# R7FA6M1AD register map
Vendor: Renesas; Series: RA6; File version: 1.2
CPU: CM4 r0p1, little endian, MPU, FPU, VTOR, 4 interrupt priority bits
Registers are 8-bit, read-write, reset 0x0 unless marked. A register's access mark holds for its fields unless they carry their own. Offsets are from the block's base; [hi:lo] are bit positions; {n}, {i} and the like mark numbered series; 'fields as' and 'values as' point back to an identical list.

## USBFS — USB 2.0 FS Module
Base 0x40090000
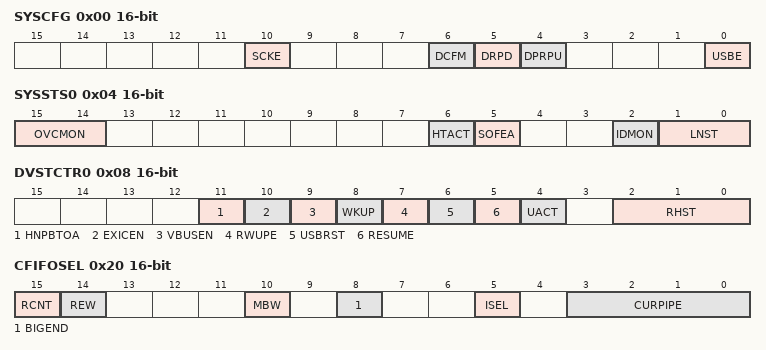
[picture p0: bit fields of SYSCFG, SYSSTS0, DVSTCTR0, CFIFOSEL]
0x00 SYSCFG 16-bit — System Configuration Control Register
  [10] SCKE — USB Clock Enable
  [6] DCFM — Controller Function Select
  [5] DRPD — D+/D- Line Resistor Control
  [4] DPRPU — D+ Line Resistor Control
  [0] USBE — USB Operation Enable
0x04 SYSSTS0 16-bit ro reset not defined — System Configuration Status Register 0
  [15:14] OVCMON — External USB0_OVRCURA/ USB0_OVRCURB Input Pin MonitorThe OCVMON[1] bit indicates the status of the USBHS_OVRCURA pin. The OCVMON[0] bit indicates the status of the USBHS_OVRCURB pin.
  [6] HTACT — USB Host Sequencer Status Monitor
  [5] SOFEA — Active Monitor When the Host Controller is Selected.
  [2] IDMON — External ID0 Input Pin Monitor
  [1:0] LNST — USB Data Line Status Monitor
0x08 DVSTCTR0 16-bit — Device State Control Register 0
  [11] HNPBTOA — Host Negotiation Protocol (HNP) Control This bit is used when switching from device B to device A while in OTG mode. If the HNPBTOA bit is 1, the internal function control keeps the suspended state until the HNP processing ends even though SYSCFG.DPRPU = 0 or SYSCFG.DCFM = 1 is set.
  [10] EXICEN — USB0_EXICEN Output Pin Control
  [9] VBUSEN — USB0_VBUSEN Output Pin Control
  [8] WKUP — Wakeup Output
  [7] RWUPE — Wakeup Detection Enable
  [6] USBRST — USB Bus Reset Output
  [5] RESUME — Resume Output
  [4] UACT — USB Bus Enable
  [2:0] RHST ro — USB Bus Reset Status
0x14 CFIFO 16-bit — CFIFO Port Register
  [15:0] FIFOPORT — FIFO PortRead receive data from the FIFO buffer or write transmit data to the FIFO buffer by accessing these bits.
0x14 CFIFOL (alternate view of CFIFO) — CFIFO Port Register L
0x18 D0FIFO 16-bit — D0FIFO Port Register
  fields as CFIFO
0x18 D0FIFOL (alternate view of D0FIFO) — D0FIFO Port Register L
0x1C D1FIFO 16-bit — D1FIFO Port Register
  fields as CFIFO
0x1C D1FIFOL (alternate view of D1FIFO) — D1FIFO Port Register L
0x20 CFIFOSEL 16-bit — CFIFO Port Select Register
  [15] RCNT — Read Count Mode
  [14] REW ro — Buffer Pointer Rewind
  [10] MBW — CFIFO Port Access Bit Width
  [8] BIGEND — CFIFO Port Endian Control
  [5] ISEL — CFIFO Port Access Direction When DCP is Selected
  [3:0] CURPIPE — CFIFO Port Access Pipe Specification
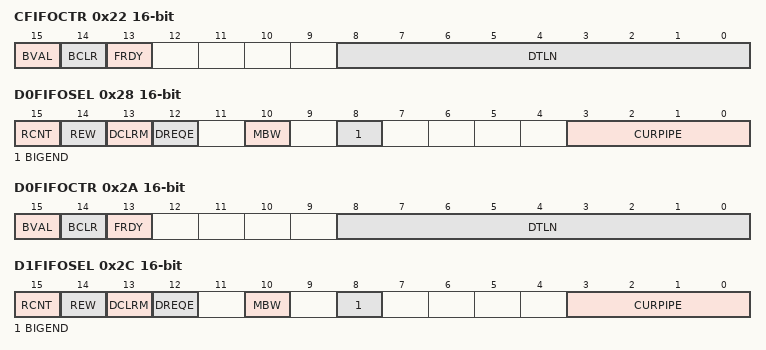
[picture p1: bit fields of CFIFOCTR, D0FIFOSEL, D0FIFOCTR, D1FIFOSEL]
0x22 CFIFOCTR 16-bit — CFIFO Port Control Register
  [15] BVAL — Buffer Memory Valid Flag
  [14] BCLR ro — CPU Buffer Clear
  [13] FRDY ro — FIFO Port Ready
  [8:0] DTLN ro — Receive Data LengthIndicates the length of the receive data.
0x28 D0FIFOSEL 16-bit — D0FIFO Port Select Register
  [15] RCNT — Read Count Mode
  [14] REW ro — Buffer Pointer Rewind
  [13] DCLRM — Auto Buffer Memory Clear Mode Accessed after Specified Pipe Data is Read
  [12] DREQE — DMA/DTC Transfer Request Enable
  [10] MBW — FIFO Port Access Bit Width
  [8] BIGEND — FIFO Port Endian Control
  [3:0] CURPIPE — FIFO Port Access Pipe Specification
0x2A D0FIFOCTR 16-bit — D0FIFO Port Control Register
  fields as CFIFOCTR
0x2C D1FIFOSEL 16-bit — D1FIFO Port Select Register
  fields as D0FIFOSEL
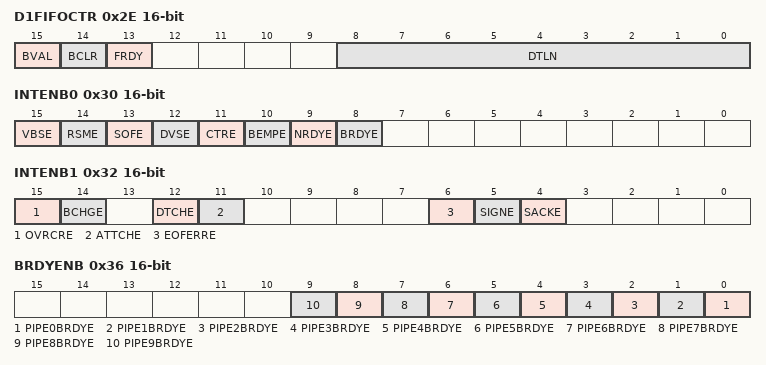
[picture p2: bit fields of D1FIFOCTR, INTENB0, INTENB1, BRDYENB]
0x2E D1FIFOCTR 16-bit — D1FIFO Port Control Register
  fields as CFIFOCTR
0x30 INTENB0 16-bit — Interrupt Enable Register 0
  [15] VBSE — VBUS Interrupt Enable
  [14] RSME — Resume Interrupt Enable
  [13] SOFE — Frame Number Update Interrupt Enable
  [12] DVSE — Device State Transition Interrupt Enable
  [11] CTRE — Control Transfer Stage Transition Interrupt Enable
  [10] BEMPE — Buffer Empty Interrupt Enable
  [9] NRDYE — Buffer Not Ready Response Interrupt Enable
  [8] BRDYE — Buffer Ready Interrupt Enable
0x32 INTENB1 16-bit — Interrupt Enable Register 1
  [15] OVRCRE — Overcurrent Input Change Interrupt Enable
  [14] BCHGE — USB Bus Change Interrupt Enable
  [12] DTCHE — Disconnection Detection Interrupt Enable
  [11] ATTCHE — Connection Detection Interrupt Enable
  [6] EOFERRE — EOF Error Detection Interrupt Enable
  [5] SIGNE — Setup Transaction Error Interrupt Enable
  [4] SACKE — Setup Transaction Normal Response Interrupt Enable
0x36 BRDYENB 16-bit — BRDY Interrupt Enable Register
  [n] PIPE{n}BRDYE (n=0..9) — BRDY Interrupt Enable for PIPE{n}
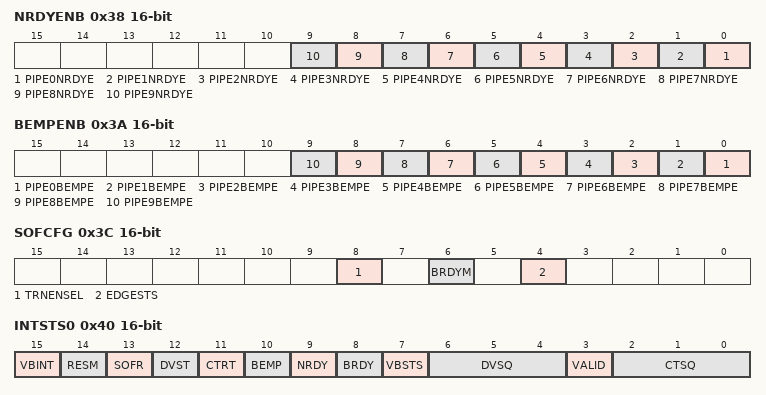
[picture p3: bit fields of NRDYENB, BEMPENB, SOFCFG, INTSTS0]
0x38 NRDYENB 16-bit — NRDY Interrupt Enable Register
  [n] PIPE{n}NRDYE (n=0..9) — NRDY Interrupt Enable for PIPE{n}
0x3A BEMPENB 16-bit — BEMP Interrupt Enable Register
  [n] PIPE{n}BEMPE (n=0..9) — BEMP Interrupt Enable for PIPE{n}
0x3C SOFCFG 16-bit — SOF Output Configuration Register
  [8] TRNENSEL — Transaction,Enabled Time Select
  [6] BRDYM — BRDY Interrupt Status Clear Timing
  [4] EDGESTS ro — Edge Interrupt Output Status Monitor
0x40 INTSTS0 16-bit (reset mask 0xFF7F) — Interrupt Status Register 0
  [15] VBINT write-0-clears read-modifies — VBUS Interrupt Status
  [14] RESM write-0-clears read-modifies — Resume Interrupt Status
  [13] SOFR write-0-clears read-modifies — Frame Number Refresh Interrupt Status
  [12] DVST write-0-clears read-modifies — Device State Transition Interrupt Status
  [11] CTRT write-0-clears read-modifies — Control Transfer Stage Transition Interrupt Status
  [10] BEMP ro — Buffer Empty Interrupt Status
  [9] NRDY ro — Buffer Not Ready Interrupt Status
  [8] BRDY ro — Buffer Ready Interrupt Status
  [7] VBSTS ro — VBUS Input Status
  [6:4] DVSQ ro — Device State
  [3] VALID — USB Request Reception
  [2:0] CTSQ ro — Control Transfer Stage
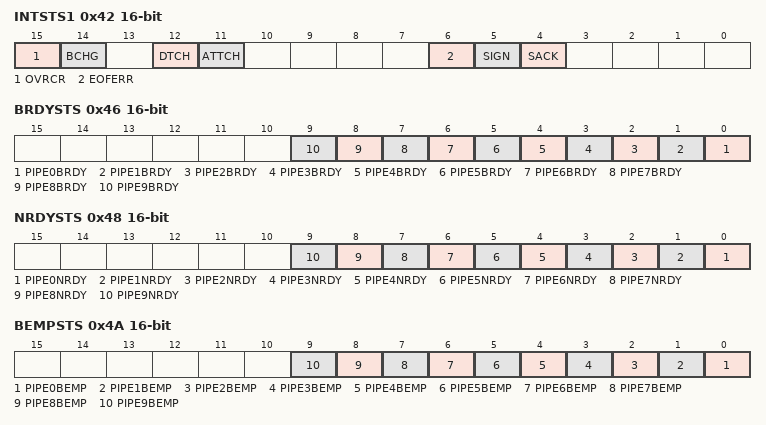
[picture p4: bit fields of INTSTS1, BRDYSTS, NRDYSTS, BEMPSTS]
0x42 INTSTS1 16-bit — Interrupt Status Register 1
  [15] OVRCR write-0-clears read-modifies — Overcurrent Input Change Interrupt Status
  [14] BCHG write-0-clears read-modifies — USB Bus Change Interrupt Status
  [12] DTCH write-0-clears read-modifies — USB Disconnection Detection Interrupt Status
  [11] ATTCH write-0-clears read-modifies — ATTCH Interrupt Status
  [6] EOFERR write-0-clears read-modifies — EOF Error Detection Interrupt Status
  [5] SIGN write-0-clears read-modifies — Setup Transaction Error Interrupt Status
  [4] SACK write-0-clears read-modifies — Setup Transaction Normal Response Interrupt Status
0x46 BRDYSTS 16-bit — BRDY Interrupt Status Register
  [n] PIPE{n}BRDY write-0-clears read-modifies (n=0..9) — BRDY Interrupt Status for PIPE{n}
0x48 NRDYSTS 16-bit — NRDY Interrupt Status Register
  [n] PIPE{n}NRDY write-0-clears read-modifies (n=0..9) — NRDY Interrupt Status for PIPE{n}
0x4A BEMPSTS 16-bit — BEMP Interrupt Status Register
  [n] PIPE{n}BEMP write-0-clears read-modifies (n=0..9) — BEMP Interrupt Status for PIPE{n}
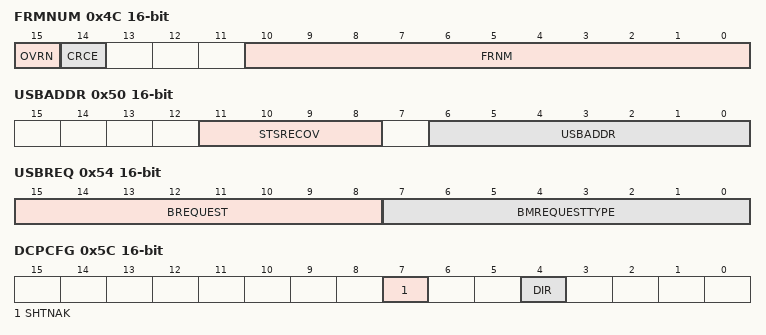
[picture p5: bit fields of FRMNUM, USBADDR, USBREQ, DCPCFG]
0x4C FRMNUM 16-bit — Frame Number Register
  [15] OVRN — Overrun/Underrun Detection Status
  [14] CRCE — Receive Data Error
  [10:0] FRNM ro — Frame NumberLatest frame number
0x4E DVCHGR 16-bit — Device State Change Register
  [15] DVCHG — Device State Change
0x50 USBADDR 16-bit — USB Address Register
  [11:8] STSRECOV — Status Recovery
  [6:0] USBADDR — USB AddressWhen the function controller is selected, these bits indicate the USB address assigned by the host when the SET_ADDRESS request is successfully processed.
0x54 USBREQ 16-bit — USB Request Type Register
  [15:8] BREQUEST — RequestThese bits store the USB request bRequest value.
  [7:0] BMREQUESTTYPE — Request TypeThese bits store the USB request bmRequestType value.
0x56 USBVAL 16-bit — USB Request Value Register
  [15:0] WVALUE — ValueThese bits store the USB request wValue value.
0x58 USBINDX 16-bit — USB Request Index Register
  [15:0] WINDEX — IndexThese bits store the USB request wIndex value.
0x5A USBLENG 16-bit — USB Request Length Register
  [15:0] WLENGTUH — LengthThese bits store the USB request wLength value.
0x5C DCPCFG 16-bit — DCP Configuration Register
  [7] SHTNAK — Pipe Disabled at End of Transfer
  [4] DIR — Transfer Direction
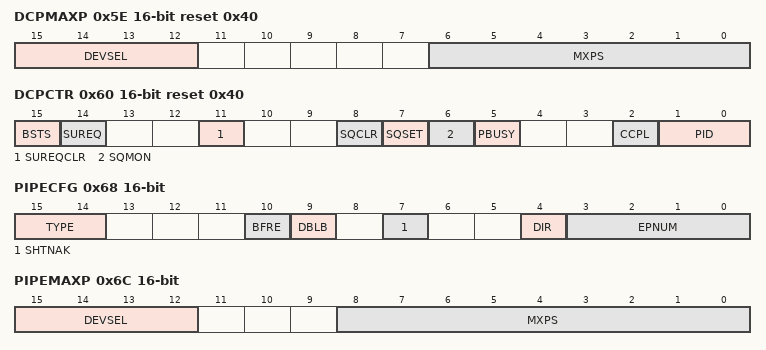
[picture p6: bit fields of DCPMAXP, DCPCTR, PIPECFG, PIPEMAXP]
0x5E DCPMAXP 16-bit reset 0x40 — DCP Maximum Packet Size Register
  [15:12] DEVSEL — Device Select
  [6:0] MXPS — Maximum Packet SizeThese bits set the maximum amount of data (maximum packet size) in payloads for the DCP.
0x60 DCPCTR 16-bit reset 0x40 — DCP Control Register
  [15] BSTS ro — Buffer Status
  [14] SUREQ — Setup Token Transmission
  [11] SUREQCLR — SUREQ Bit Clear
  [8] SQCLR — Sequence Toggle Bit Clear
  [7] SQSET — Sequence Toggle Bit Set
  [6] SQMON ro — Sequence Toggle Bit Monitor
  [5] PBUSY ro — Pipe Busy
  [2] CCPL — Control Transfer End Enable
  [1:0] PID — Response PID
0x64 PIPESEL 16-bit — Pipe Window Select Register
  [3:0] PIPESEL — Pipe Window Select
0x68 PIPECFG 16-bit — Pipe Configuration Register
  [15:14] TYPE — Transfer Type
  [10] BFRE — BRDY Interrupt Operation Specification
  [9] DBLB — Double Buffer Mode
  [7] SHTNAK — Pipe Disabled at End of Transfer
  [4] DIR — Transfer Direction
  [3:0] EPNUM — Endpoint NumberThese bits specify the endpoint number for the selected pipe.Setting 0000b means unused pipe.
0x6C PIPEMAXP 16-bit (reset mask 0xFFBF) — Pipe Maximum Packet Size Register
  [15:12] DEVSEL — Device Select
  [8:0] MXPS — Maximum Packet SizePIPE1 and PIPE2: 1 byte (001h) to 256 bytes (100h)PIPE3 to PIPE5: 8 bytes (008h), 16 bytes (010h), 32 bytes (020h), 64 bytes (040h) (Bits [8:7] and [2:0] are not provided.)PIPE6 to PIPE9: 1 byte (001h) to 64 bytes (040h) (Bits [8:7] are not provided.)
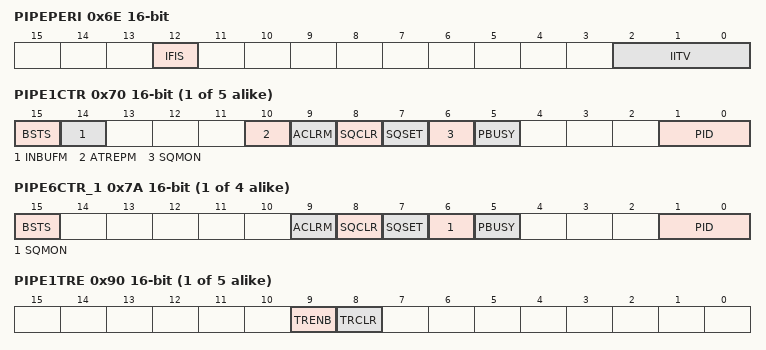
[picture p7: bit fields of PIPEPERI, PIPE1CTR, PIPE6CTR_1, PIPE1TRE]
0x6E PIPEPERI 16-bit — Pipe Cycle Control Register
  [12] IFIS — Isochronous IN Buffer Flush
  [2:0] IITV — Interval Error Detection IntervalSpecifies the interval error detection timing for the selected pipe in terms of frames, which is expressed as nth power of 2.
{0x6E+2i} PIPE{i}CTR (i=1..5) 16-bit — Pipe {i} Control Register
  [15] BSTS ro — Buffer Status
  [14] INBUFM ro — Transmit Buffer Monitor
  [10] ATREPM — Auto Response Mode
  [9] ACLRM — Auto Buffer Clear Mode
  [8] SQCLR wo — Sequence Toggle Bit Clear
  [7] SQSET wo — Sequence Toggle Bit Set
  [6] SQMON ro — Sequence Toggle Bit Confirmation
  [5] PBUSY ro — Pipe Busy
  [1:0] PID — Response PID
{0x6E+2i} PIPE{i}CTR_1 (i=6..9) 16-bit — Pipe {i} Control Register
  [15] BSTS ro — Buffer Status
  [9] ACLRM — Auto Buffer Clear Mode
  [8] SQCLR wo — Sequence Toggle Bit Clear
  [7] SQSET wo — Sequence Toggle Bit Set
  [6] SQMON ro — Sequence Toggle Bit Confirmation
  [5] PBUSY ro — Pipe Busy
  [1:0] PID — Response PID
{0x8C+4i} PIPE{i}TRE (i=1..5) 16-bit — Pipe {i} Transaction Counter Enable Register
  [9] TRENB — Transaction Counter Enable
  [8] TRCLR — Transaction Counter Clear
{0x8E+4i} PIPE{i}TRN (i=1..5) 16-bit — Pipe {i} Transaction Counter Register
  [15:0] TRNCNT — Transaction Counter
{0xD0+2i} DEVADD{i} (i=0..5) 16-bit — Device Address {i} Configuration Register
  [7:6] USBSPD — Transfer Speed of Communication Target Device
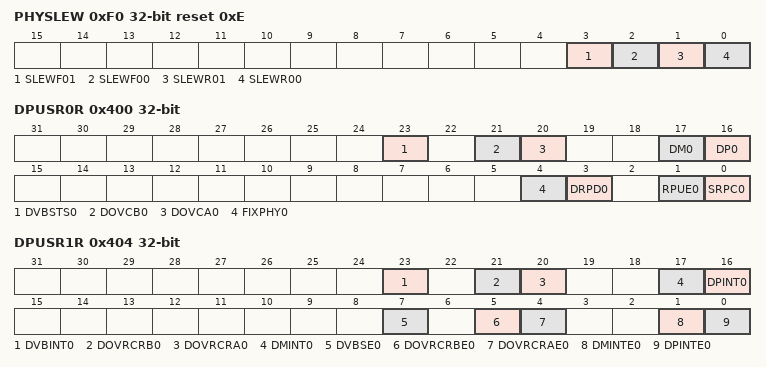
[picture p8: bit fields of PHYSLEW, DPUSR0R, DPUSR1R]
0xF0 PHYSLEW 32-bit reset 0xE — PHY Cross Point Adjustment Register
  [3] SLEWF01 — Receiver Cross Point Adjustment 01
  [2] SLEWF00 — Receiver Cross Point Adjustment 00
  [1] SLEWR01 — Receiver Cross Point Adjustment 01
  [0] SLEWR00 — Receiver Cross Point Adjustment 00
0x400 DPUSR0R 32-bit (reset mask 0xFF4CFFFF) — Deep Software Standby USB Transceiver Control/Pin Monitor Register
  [23] DVBSTS0 ro — USB VBUS InputIndicates the VBUS input signal of the USB.
  [21] DOVCB0 ro — USB OVRCURB InputIndicates the OVRCURB input signal of the USB.
  [20] DOVCA0 ro — USB OVRCURA InputIndicates the OVRCURA input signal of the USB.
  [17] DM0 ro — USB D,InputIndicates the D- input signal of the USB.
  [16] DP0 ro — USB0 D+ InputIndicates the D+ input signal of the USB.
  [4] FIXPHY0 — USB Transceiver Output Fix
  [3] DRPD0 — D+/D- Pull,Down Resistor Control
  [1] RPUE0 — DP Pull,Up Resistor Control
  [0] SRPC0 — USB Single End Receiver Control
0x404 DPUSR1R 32-bit — Deep Software Standby USB Suspend/Resume Interrupt Register
  [23] DVBINT0 ro — USB VBUS Interrupt Source Recovery
  [21] DOVRCRB0 ro — USB OVRCURB Interrupt Source Recovery
  [20] DOVRCRA0 ro — USB OVRCURA Interrupt Source Recovery
  [17] DMINT0 ro — USB DM Interrupt Source Recovery
  [16] DPINT0 ro — USB DP Interrupt Source Recovery
  [7] DVBSE0 — USB VBUS Interrupt Enable/Clear
  [5] DOVRCRBE0 — USB OVRCURB Interrupt Enable/Clear
  [4] DOVRCRAE0 — USB OVRCURA Interrupt Enable/Clear
  [1] DMINTE0 — USB DM Interrupt Enable/Clear
  [0] DPINTE0 — USB DP Interrupt Enable/Clear
